AUTOSAR XML (schema 4-0-3)
standard types defined: Boolean, UInt16, UInt32, UInt8
package /AUTOSAR_Platform/DataConstrs
  range DC_Boolean: raw 0..1
  range DC_UInt16: raw 0..65535
  range DC_UInt8: raw 0..255
package /PATAC/MSM/ComponentTypes
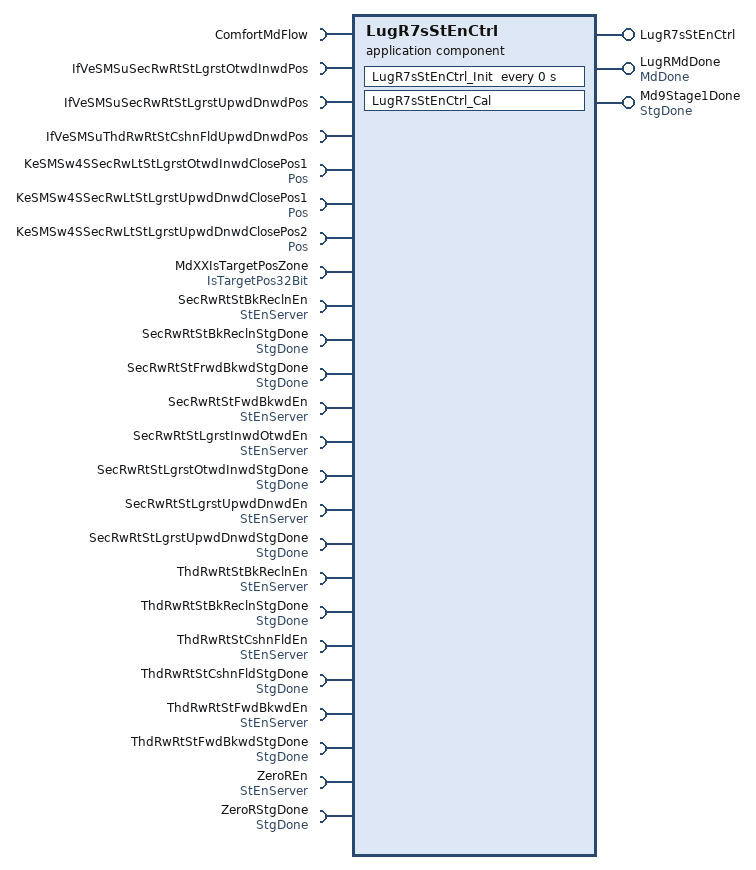
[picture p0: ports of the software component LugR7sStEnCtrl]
  application sw component type LugR7sStEnCtrl
    provide port LugR7sStEnCtrl: server-com-spec{operation=LugR7sStEnCtrl/Cal, queue-length=1}, provided-interface=LugR7sStEnCtrl
    provide port LugRMdDone: nonqueued-sender-com-spec{data-element=MdDone/Val, init-value=0}, provided-interface=MdDone
    provide port Md9Stage1Done: nonqueued-sender-com-spec{data-element=StgDone/Val, init-value=0}, provided-interface=StgDone
    24 x require port:
      ComfortMdFlow: client-com-spec=ComfortMdFlow/Cal, required-interface=ComfortMdFlow
      IfVeSMSuSecRwRtStLgrstOtwdInwdPos: nonqueued-receiver-com-spec{data-element=IfVeSMSuSecRwRtStLgrstOtwdInwdPos/Val, filter=data-filter-type=ALWAYS, init-value=0}, required-interface=IfVeSMSuSecRwRtStLgrstOtwdInwdPos
      IfVeSMSuSecRwRtStLgrstUpwdDnwdPos: nonqueued-receiver-com-spec{data-element=IfVeSMSuSecRwRtStLgrstUpwdDnwdPos/Val, filter=data-filter-type=ALWAYS, init-value=0}, required-interface=IfVeSMSuSecRwRtStLgrstUpwdDnwdPos
      IfVeSMSuThdRwRtStCshnFldUpwdDnwdPos: nonqueued-receiver-com-spec{data-element=IfVeSMSuThdRwRtStCshnFldUpwdDnwdPos/Val, filter=data-filter-type=ALWAYS, init-value=0}, required-interface=IfVeSMSuThdRwRtStCshnFldUpwdDnwdPos
      KeSMSw4SSecRwLtStLgrstOtwdInwdClosePos1: parameter-require-com-spec{init-value=0, parameter=Val}, required-interface=Pos
      KeSMSw4SSecRwLtStLgrstUpwdDnwdClosePos1: parameter-require-com-spec{init-value=0, parameter=Val}, required-interface=Pos
      KeSMSw4SSecRwLtStLgrstUpwdDnwdClosePos2: parameter-require-com-spec{init-value=0, parameter=Val}, required-interface=Pos
      MdXXIsTargetPosZone: nonqueued-receiver-com-spec{data-element=IsTargetPos32Bit/Val, filter=data-filter-type=ALWAYS, init-value=0}, required-interface=IsTargetPos32Bit
      SecRwRtStBkReclnEn: required-com-specs=[Clear, Get, Set], required-interface=StEnServer
      SecRwRtStBkReclnStgDone: nonqueued-receiver-com-spec{data-element=StgDone/Val, filter=data-filter-type=ALWAYS, init-value=0}, required-interface=StgDone
      SecRwRtStFrwdBkwdStgDone: nonqueued-receiver-com-spec{data-element=StgDone/Val, filter=data-filter-type=ALWAYS, init-value=0}, required-interface=StgDone
      SecRwRtStFwdBkwdEn: required-com-specs=[Clear, Get, Set], required-interface=StEnServer
      SecRwRtStLgrstInwdOtwdEn: required-com-specs=[Clear, Get, Set], required-interface=StEnServer
      SecRwRtStLgrstOtwdInwdStgDone: nonqueued-receiver-com-spec{data-element=StgDone/Val, filter=data-filter-type=ALWAYS, init-value=0}, required-interface=StgDone
      SecRwRtStLgrstUpwdDnwdEn: required-com-specs=[Clear, Get, Set], required-interface=StEnServer
      SecRwRtStLgrstUpwdDnwdStgDone: nonqueued-receiver-com-spec{data-element=StgDone/Val, filter=data-filter-type=ALWAYS, init-value=0}, required-interface=StgDone
      ThdRwRtStBkReclnEn: required-com-specs=[Clear, Get, Set], required-interface=StEnServer
      ThdRwRtStBkReclnStgDone: nonqueued-receiver-com-spec{data-element=StgDone/Val, filter=data-filter-type=ALWAYS, init-value=0}, required-interface=StgDone
      ThdRwRtStCshnFldEn: required-com-specs=[Clear, Get, Set], required-interface=StEnServer
      ThdRwRtStCshnFldStgDone: nonqueued-receiver-com-spec{data-element=StgDone/Val, filter=data-filter-type=ALWAYS, init-value=0}, required-interface=StgDone
      ThdRwRtStFwdBkwdEn: required-com-specs=[Clear, Get, Set], required-interface=StEnServer
      ThdRwRtStFwdBkwdStgDone: nonqueued-receiver-com-spec{data-element=StgDone/Val, filter=data-filter-type=ALWAYS, init-value=0}, required-interface=StgDone
      ZeroREn: required-com-specs=[Clear, Get, Set], required-interface=StEnServer
      ZeroRStgDone: nonqueued-receiver-com-spec{data-element=StgDone/Val, filter=data-filter-type=ALWAYS, init-value=0}, required-interface=StgDone
    behavior LugR7sStEnCtrl_InternalBehavior
      operation invoked event OIT_LugR7sStEnCtrl_Cal_LugR7sStEnCtrl_Cal: start-on-event=LugR7sStEnCtrl_Cal, operation=LugR7sStEnCtrl.Cal
      timing event LugR7sStEnCtrl_InitEvent: start-on-event=LugR7sStEnCtrl_Init, period=0
      runnable LugR7sStEnCtrl_Cal
        data-receive-point-by-arguments:
          12 x access:
            REC_IfVeSMSuSecRwRtStLgrstOtwdInwdPos_Val: accessed-variable=IfVeSMSuSecRwRtStLgrstOtwdInwdPos.Val
            REC_IfVeSMSuSecRwRtStLgrstUpwdDnwdPos_Val: accessed-variable=IfVeSMSuSecRwRtStLgrstUpwdDnwdPos.Val
            REC_IfVeSMSuThdRwRtStCshnFldUpwdDnwdPos_Val: accessed-variable=IfVeSMSuThdRwRtStCshnFldUpwdDnwdPos.Val
            REC_MdXXIsTargetPosZone_Val: accessed-variable=MdXXIsTargetPosZone.Val
            REC_SecRwRtStBkReclnStgDone_Val: accessed-variable=SecRwRtStBkReclnStgDone.Val
            REC_SecRwRtStFrwdBkwdStgDone_Val: accessed-variable=SecRwRtStFrwdBkwdStgDone.Val
            REC_SecRwRtStLgrstOtwdInwdStgDone_Val: accessed-variable=SecRwRtStLgrstOtwdInwdStgDone.Val
            REC_SecRwRtStLgrstUpwdDnwdStgDone_Val: accessed-variable=SecRwRtStLgrstUpwdDnwdStgDone.Val
            REC_ThdRwRtStBkReclnStgDone_Val: accessed-variable=ThdRwRtStBkReclnStgDone.Val
            REC_ThdRwRtStCshnFldStgDone_Val: accessed-variable=ThdRwRtStCshnFldStgDone.Val
            REC_ThdRwRtStFwdBkwdStgDone_Val: accessed-variable=ThdRwRtStFwdBkwdStgDone.Val
            REC_ZeroRStgDone_Val: accessed-variable=ZeroRStgDone.Val
        data-send-points:
          access SEND_LugRMdDone_Val: accessed-variable=LugRMdDone.Val
          access SEND_Md9Stage1Done_Val: accessed-variable=Md9Stage1Done.Val
        parameter access PA_KeSMSw4SSecRwLtStLgrstOtwdInwdClosePos1_Val: accessed-parameter=KeSMSw4SSecRwLtStLgrstOtwdInwdClosePos1.Val
        parameter access PA_KeSMSw4SSecRwLtStLgrstUpwdDnwdClosePos1_Val: accessed-parameter=KeSMSw4SSecRwLtStLgrstUpwdDnwdClosePos1.Val
        parameter access PA_KeSMSw4SSecRwLtStLgrstUpwdDnwdClosePos2_Val: accessed-parameter=KeSMSw4SSecRwLtStLgrstUpwdDnwdClosePos2.Val
        17 x sync call, all with timeout=0:
          SC_ComfortMdFlow_Cal: operation=ComfortMdFlow.Cal
          SC_SecRwRtStBkReclnEn_Clear: operation=SecRwRtStBkReclnEn.Clear
          SC_SecRwRtStBkReclnEn_Set: operation=SecRwRtStBkReclnEn.Set
          SC_SecRwRtStFwdBkwdEn_Clear: operation=SecRwRtStFwdBkwdEn.Clear
          SC_SecRwRtStFwdBkwdEn_Set: operation=SecRwRtStFwdBkwdEn.Set
          SC_SecRwRtStLgrstInwdOtwdEn_Clear: operation=SecRwRtStLgrstInwdOtwdEn.Clear
          SC_SecRwRtStLgrstInwdOtwdEn_Set: operation=SecRwRtStLgrstInwdOtwdEn.Set
          SC_SecRwRtStLgrstUpwdDnwdEn_Clear: operation=SecRwRtStLgrstUpwdDnwdEn.Clear
          SC_SecRwRtStLgrstUpwdDnwdEn_Set: operation=SecRwRtStLgrstUpwdDnwdEn.Set
          SC_ThdRwRtStBkReclnEn_Clear: operation=ThdRwRtStBkReclnEn.Clear
          SC_ThdRwRtStBkReclnEn_Set: operation=ThdRwRtStBkReclnEn.Set
          SC_ThdRwRtStCshnFldEn_Clear: operation=ThdRwRtStCshnFldEn.Clear
          SC_ThdRwRtStCshnFldEn_Set: operation=ThdRwRtStCshnFldEn.Set
          SC_ThdRwRtStFwdBkwdEn_Clear: operation=ThdRwRtStFwdBkwdEn.Clear
          SC_ThdRwRtStFwdBkwdEn_Set: operation=ThdRwRtStFwdBkwdEn.Set
          SC_ZeroREn_Clear: operation=ZeroREn.Clear
          SC_ZeroREn_Set: operation=ZeroREn.Set
      runnable LugR7sStEnCtrl_Init
        parameter access PA_KeSMSw4SSecRwLtStLgrstOtwdInwdClosePos1_Val: accessed-parameter=KeSMSw4SSecRwLtStLgrstOtwdInwdClosePos1.Val
        parameter access PA_KeSMSw4SSecRwLtStLgrstUpwdDnwdClosePos1_Val: accessed-parameter=KeSMSw4SSecRwLtStLgrstUpwdDnwdClosePos1.Val
        parameter access PA_KeSMSw4SSecRwLtStLgrstUpwdDnwdClosePos2_Val: accessed-parameter=KeSMSw4SSecRwLtStLgrstUpwdDnwdClosePos2.Val
  swc implementation LugR7sStEnCtrl_Implementation: behavior=LugR7sStEnCtrl_InternalBehavior
    code-descriptors:
      code Default: artifact-descriptors=autosar-engineering-object={short-label=Default, category=SWSRC}
package /PATAC/MSM/ModeAdjust/CalPortInterface
  parameter interface Pos
    parameter data prototype Val: sw-calibration-access=READ-WRITE, type=UInt16
package /PATAC/MSM/ModeAdjust/Interfaces
  sender receiver interface IfVeSMSuThdRwRtStCshnFldUpwdDnwdPos: invalidation-policy{data-element=IfVeSMSuThdRwRtStCshnFldUpwdDnwdPos/Val, handle-invalid=DONT-INVALIDATE}
    data Val: type=UInt16
package /PATAC/MSM/ModeAdjust/PortInterface
  client server interface ComfortMdFlow
    operation Cal
      14 x arg, all with server-argument-impl-policy=USE-ARGUMENT-TYPE:
        LgrstUpwdDnwdPos: type=UInt16, direction=IN
        LgrstUpwdDnwdClosePos1: type=UInt16, direction=IN
        LgrstUpwdStgDone: type=Implementation/Boolean, direction=IN
        ZeroStgDone: type=Implementation/Boolean, direction=IN
        LgrstInwdStgDone: type=Implementation/Boolean, direction=IN
        Failflg: type=Implementation/Boolean, direction=OUT
        LgrstInwdOtwdEn: type=Implementation/Boolean, direction=OUT
        LgrstUpwdDnwdEn: type=Implementation/Boolean, direction=OUT
        ZeroEn: type=Implementation/Boolean, direction=OUT
        BkReclnStgDone: type=DataTypes/Boolean, direction=IN
        BkReclnEn: type=DataTypes/Boolean, direction=OUT
        LgrstUpwdDnwdClosePos2: type=UInt16, direction=IN
        LgrstInwdOtwdClosePos1: type=UInt16, direction=IN
        LgrstInwdOtwdPos: type=UInt16, direction=IN
  client server interface LugR7sStEnCtrl
    operation Cal
  client server interface StEnServer
    operation Clear
      arg data: type=UInt8, direction=IN, server-argument-impl-policy=USE-ARGUMENT-TYPE
    operation Get
      arg data: type=UInt32, direction=OUT, server-argument-impl-policy=USE-ARGUMENT-TYPE
    operation Set
      arg data: type=UInt8, direction=IN, server-argument-impl-policy=USE-ARGUMENT-TYPE
  sender receiver interface IsTargetPos32Bit: invalidation-policy{data-element=IsTargetPos32Bit/Val, handle-invalid=DONT-INVALIDATE}
    data Val: type=UInt32
  sender receiver interface MdDone: invalidation-policy{data-element=MdDone/Val, handle-invalid=DONT-INVALIDATE}
    data Val: type=UInt8
  sender receiver interface StgDone: invalidation-policy{data-element=StgDone/Val, handle-invalid=DONT-INVALIDATE}
    data Val: type=Implementation/Boolean
package /PATAC/MSM/PortInterfaces
  sender receiver interface IfVeSMSuSecRwRtStLgrstOtwdInwdPos: invalidation-policy{data-element=IfVeSMSuSecRwRtStLgrstOtwdInwdPos/Val, handle-invalid=DONT-INVALIDATE}
    data Val: type=UInt16
  sender receiver interface IfVeSMSuSecRwRtStLgrstUpwdDnwdPos: invalidation-policy{data-element=IfVeSMSuSecRwRtStLgrstUpwdDnwdPos/Val, handle-invalid=DONT-INVALIDATE}
    data Val: type=UInt16
